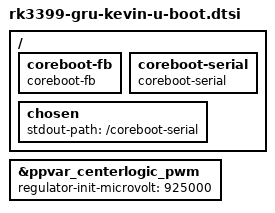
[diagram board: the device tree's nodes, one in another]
// SPDX-License-Identifier: GPL-2.0+
/*
 * Copyright (C) 2019 Jagan Teki <jagan@amarulasolutions.com>
 */

#include "rk3399-gru-u-boot.dtsi"
#include "rk3399-sdram-lpddr3-samsung-4GB-1866.dtsi"

/ {
        coreboot-fb {
                bootph-some-ram;
                compatible = "coreboot-fb";
        };

        coreboot-serial {
                compatible = "coreboot-serial";
        };

        chosen {
                stdout-path = "/coreboot-serial";
        };
};

&ppvar_centerlogic_pwm {
	regulator-init-microvolt = <925000>;
};
